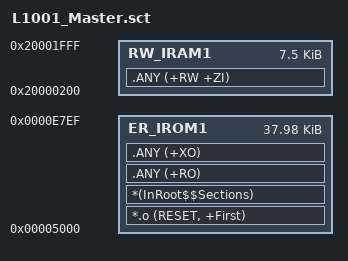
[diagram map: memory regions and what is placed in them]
; *************************************************************
; *** Scatter-Loading Description File generated by uVision ***
; *************************************************************

LR_IROM1 0x00005000 0x000097F0  {    ; load region size_region
  ER_IROM1 0x00005000 0x000097F0  {  ; load address = execution address
   *.o (RESET, +First)
   *(InRoot$$Sections)
   .ANY (+RO)
   .ANY (+XO)
  }
  RW_IRAM1 0x20000200 0x00001E00  {  ; RW data
   .ANY (+RW +ZI)
  }
}

